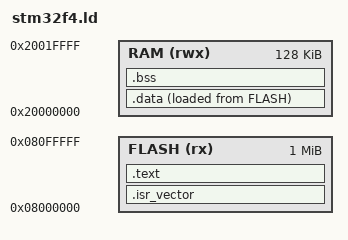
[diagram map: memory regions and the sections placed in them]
/* STM32F407: 1 MB flash, 128 KB main RAM. Adjust LENGTH for your part (see its datasheet). */
MEMORY
{
  FLASH (rx)  : ORIGIN = 0x08000000, LENGTH = 1024K
  RAM   (rwx) : ORIGIN = 0x20000000, LENGTH = 128K
}

_estack = ORIGIN(RAM) + LENGTH(RAM);
ENTRY(Reset_Handler)

SECTIONS
{
  .isr_vector : { KEEP(*(.isr_vector)) } > FLASH
  .text       : { *(.text*) *(.rodata*) . = ALIGN(4); _etext = .; } > FLASH
  .data       : { _sdata = .; *(.data*) . = ALIGN(4); _edata = .; } > RAM AT > FLASH
  _sidata = LOADADDR(.data);
  .bss        : { _sbss = .; *(.bss*) *(COMMON) . = ALIGN(4); _ebss = .; } > RAM
}
